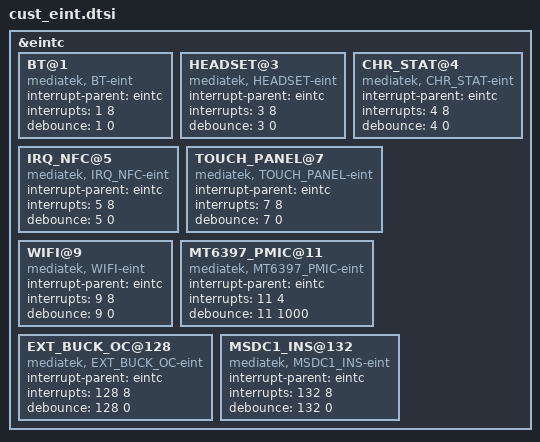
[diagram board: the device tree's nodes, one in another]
/*
 * Generated by MTK SP DrvGen Version 03.13.6 for MT8173. Copyright MediaTek Inc. (C) 2013.
 * Wed Oct 22 14:50:31 2014
 * Do Not Modify the File.
 */

/*************************
 * EINT DTSI File
*************************/

&eintc {
	BT@1 {
		compatible = "mediatek, BT-eint";
		interrupt-parent = <&eintc>;
		interrupts = <1 8>;
		debounce = <1 0>;
	};

	HEADSET@3 {
		compatible = "mediatek, HEADSET-eint";
		interrupt-parent = <&eintc>;
		interrupts = <3 8>;
		debounce = <3 0>;
	};

	CHR_STAT@4 {
		compatible = "mediatek, CHR_STAT-eint";
		interrupt-parent = <&eintc>;
		interrupts = <4 8>;
		debounce = <4 0>;
	};

	IRQ_NFC@5 {
		compatible = "mediatek, IRQ_NFC-eint";
		interrupt-parent = <&eintc>;
		interrupts = <5 8>;
		debounce = <5 0>;
	};

	TOUCH_PANEL@7 {
		compatible = "mediatek, TOUCH_PANEL-eint";
		interrupt-parent = <&eintc>;
		interrupts = <7 8>;
		debounce = <7 0>;
	};

	WIFI@9 {
		compatible = "mediatek, WIFI-eint";
		interrupt-parent = <&eintc>;
		interrupts = <9 8>;
		debounce = <9 0>;
	};

	MT6397_PMIC@11 {
		compatible = "mediatek, MT6397_PMIC-eint";
		interrupt-parent = <&eintc>;
		interrupts = <11 4>;
		debounce = <11 1000>;
	};

	EXT_BUCK_OC@128 {
		compatible = "mediatek, EXT_BUCK_OC-eint";
		interrupt-parent = <&eintc>;
		interrupts = <128 8>;
		debounce = <128 0>;
	};

	MSDC1_INS@132 {
		compatible = "mediatek, MSDC1_INS-eint";
		interrupt-parent = <&eintc>;
		interrupts = <132 8>;
		debounce = <132 0>;
	};

};
